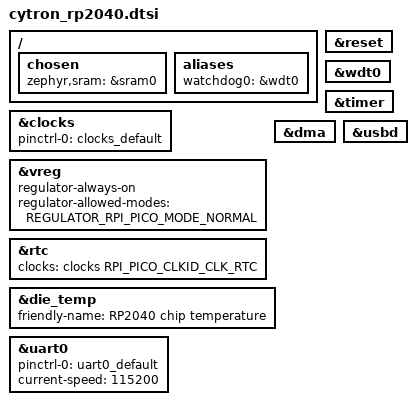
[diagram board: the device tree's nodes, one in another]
/*
 * Copyright (c) 2023-2025 TiaC Systems
 * SPDX-License-Identifier: Apache-2.0
 */

#include <mem.h>
#include <raspberrypi/rpi_pico/rp2040.dtsi>
#include <zephyr/dt-bindings/regulator/rpi_pico.h>

#include "cytron_rp2040-pinctrl.dtsi"

/ {
	chosen {
		zephyr,sram = &sram0;
	};

	aliases {
		watchdog0 = &wdt0;
	};
};

&clocks {
	pinctrl-0 = <&clocks_default>;
	pinctrl-names = "default";
};

&vreg {
	regulator-always-on;
	regulator-allowed-modes = <REGULATOR_RPI_PICO_MODE_NORMAL>;
};

&reset {
	status = "okay";
};

&wdt0 {
	status = "okay";
};

&rtc {
	clocks = <&clocks RPI_PICO_CLKID_CLK_RTC>;
	status = "okay";
};

&timer {
	status = "okay";
};

&dma {
	status = "okay";
};

&die_temp {
	status = "okay";
	friendly-name = "RP2040 chip temperature";
};

&uart0 {
	status = "okay";
	pinctrl-0 = <&uart0_default>;
	pinctrl-names = "default";
	current-speed = <115200>;
};

zephyr_udc0: &usbd {
	status = "okay";
};
